# CMS32L032 register map
Vendor: CMS; Series: CMS32L032; File version: 1.2
CPU: CM0+ r0p1, little endian, no MPU, no FPU, VTOR, 2 interrupt priority bits
Registers are 8-bit, read-write, reset 0x0 unless marked. A register's access mark holds for its fields unless they carry their own. Offsets are from the block's base; [hi:lo] are bit positions; {n}, {i} and the like mark numbered series; 'fields as' and 'values as' point back to an identical list.

## SCI0 — Serial Communication Interface 0 with UART, SPI and simplified I2C supported
Base 0x40041100
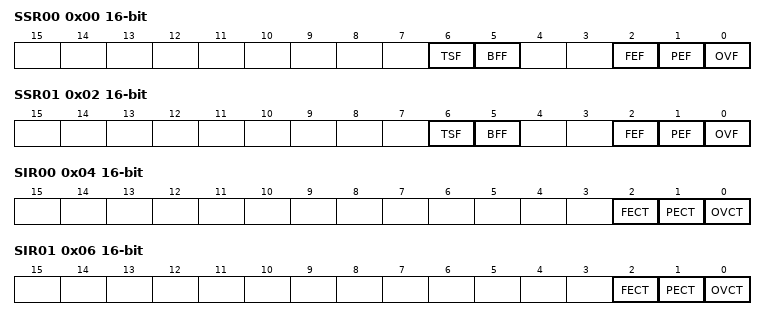
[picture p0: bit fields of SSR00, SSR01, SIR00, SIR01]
0x00 SSR00 16-bit ro — Serial status register mn
  [6] TSF — Communication status indication flag of channel n
  [5] BFF — Buffer register status indication flag of channel n
  [2] FEF — Framing error detection flag of channel n
  [1] PEF — Parity error detection flag of channel n
  [0] OVF — Overrun error detection flag of channel n
0x02 SSR01 16-bit ro — Serial status register mn
  fields as SSR00
0x04 SIR00 16-bit — Serial flag clear trigger register mn
  [2] FECT — Clear trigger of framing error flag of channel n
  [1] PECT — Clear trigger of parity error flag of channel n
  [0] OVCT — Clear trigger of overrun error flag of channel n
0x06 SIR01 16-bit — Serial flag clear trigger register mn
  fields as SIR00
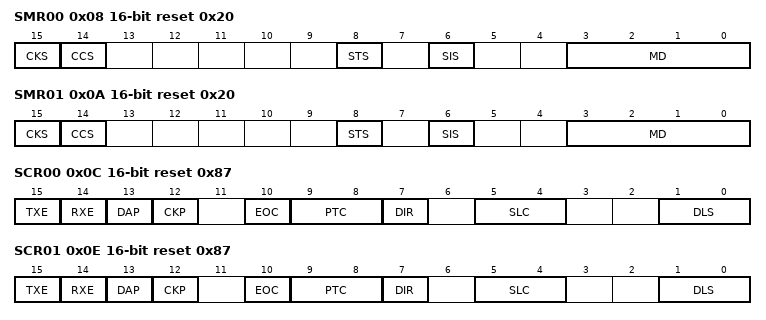
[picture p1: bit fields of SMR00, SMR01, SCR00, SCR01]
0x08 SMR00 16-bit reset 0x20 (reset mask 0xC147) — Serial mode register mn
  [15] CKS — Selection of operation clock (fMCK) of channel n
  [14] CCS — Selection of transfer clock (fTCLK) of channel n
  [8] STS — Selection of start trigger source
  [6] SIS — Controls inversion of level of receive data of channel n in UART mode
  [3:0] MD — Setting of operation mode of channel n
0x0A SMR01 16-bit reset 0x20 (reset mask 0xC147) — Serial mode register mn
  fields as SMR00
0x0C SCR00 16-bit reset 0x87 — Serial communication operation setting register mn
  [15] TXE — Transmission enable
  [14] RXE — Reception enable
  [13] DAP — Selection of data phase in SPI mode
  [12] CKP — Selection of clock phase in SPI mode
  [10] EOC — Mask control of error interrupt signal (INTSREx (x = 0 to 2))
  [9:8] PTC — Setting of parity bit in UART mode
  [7] DIR — Selection of data transfer sequence in SPI and UART modes
  [5:4] SLC — Setting of stop bit in UART mode
  [1:0] DLS — Setting of data length in SPI and UART modes
0x0E SCR01 16-bit reset 0x87 — Serial communication operation setting register mn
  fields as SCR00
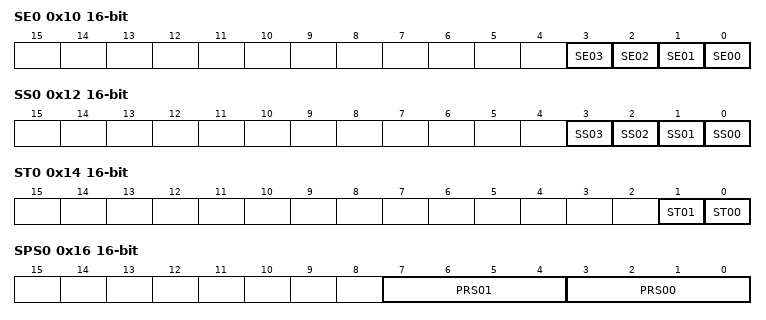
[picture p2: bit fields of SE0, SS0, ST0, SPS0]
0x10 SE0 16-bit ro — Serial channel enable status register m
  [n] SE{n:02} (n=0..3) — Indication of operation enable/stop status of channel {n}
0x12 SS0 16-bit — Serial channel start register 0
  [n] SS{n:02} (n=0..3) — Operation start trigger of channel {n}
0x14 ST0 16-bit — Serial channel stop register 0
  [1] ST01 — Operation stop trigger of channel 1
  [0] ST00 — Operation stop trigger of channel 0
0x16 SPS0 16-bit — Serial clock select register 0
  [7:4] PRS01 — Prescaler 1
  [3:0] PRS00 — Prescaler 0
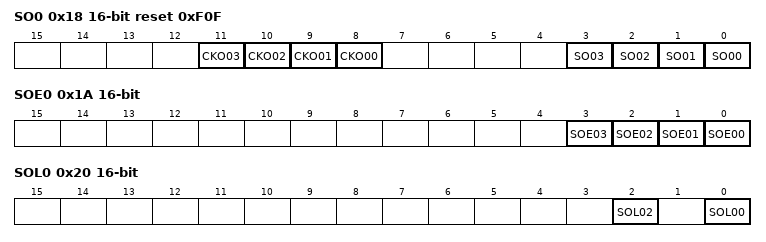
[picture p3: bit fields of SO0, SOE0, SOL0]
0x18 SO0 16-bit reset 0xF0F — Serial output register 0
  [n+8] CKO{n:02} (n=0..3) — Serial clock output of channel {n}
  [n] SO{n:02} (n=0..3) — Serial data output of channel {n}
0x1A SOE0 16-bit — Serial output enable register 0
  [n] SOE{n:02} (n=0..3) — Serial output enable of channel {n}
0x20 SOL0 16-bit — Serial output level register 0
  [2] SOL02 — Selects inversion of the level of the transmit data of channel n in UART mode
  [0] SOL00 — Selects inversion of the level of the transmit data of channel n in UART mode
0x22 SSE0 16-bit — Chip select register 0
  [0] SSE00 — Selects chip input
{0x40+2i} SDR0{i} (i=0..1) 16-bit — Serial data register 0{i}
0x40 SIO00 (alternate view of SDR00) — SPI data register
0x40 TXD0 (alternate view of SDR00) — UART transmit data register
0x42 SIO01 (alternate view of SDR01) — SPI data register
0x42 RXD0 (alternate view of SDR01) — UART receive data register

## SCI1 — Serial Communication Interface 1 with UART, SPI and simplified I2C supported
Base 0x40041500
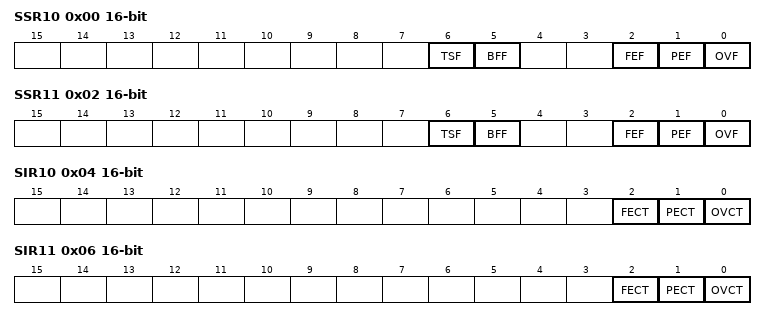
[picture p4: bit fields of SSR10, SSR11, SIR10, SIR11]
0x00 SSR10 16-bit ro — Serial status register mn
  [6] TSF — Communication status indication flag of channel n
  [5] BFF — Buffer register status indication flag of channel n
  [2] FEF — Framing error detection flag of channel n
  [1] PEF — Parity error detection flag of channel n
  [0] OVF — Overrun error detection flag of channel n
0x02 SSR11 16-bit ro — Serial status register mn
  fields as SSR10
0x04 SIR10 16-bit — Serial flag clear trigger register mn
  [2] FECT — Clear trigger of framing error flag of channel n
  [1] PECT — Clear trigger of parity error flag of channel n
  [0] OVCT — Clear trigger of overrun error flag of channel n
0x06 SIR11 16-bit — Serial flag clear trigger register mn
  fields as SIR10
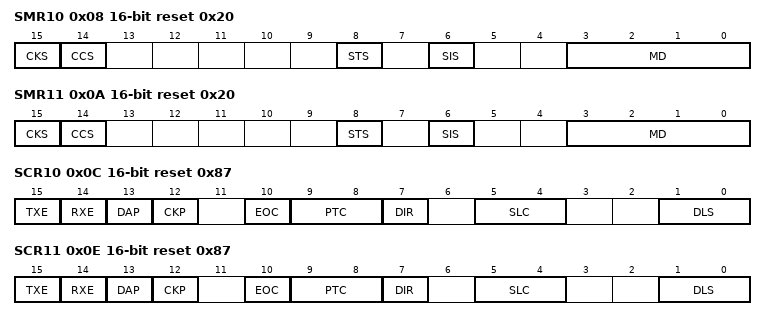
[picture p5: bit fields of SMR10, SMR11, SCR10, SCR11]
0x08 SMR10 16-bit reset 0x20 (reset mask 0xC147) — Serial mode register mn
  [15] CKS — Selection of operation clock (fMCK) of channel n
  [14] CCS — Selection of transfer clock (fTCLK) of channel n
  [8] STS — Selection of start trigger source
  [6] SIS — Controls inversion of level of receive data of channel n in UART mode
  [3:0] MD — Setting of operation mode of channel n
0x0A SMR11 16-bit reset 0x20 (reset mask 0xC147) — Serial mode register mn
  fields as SMR10
0x0C SCR10 16-bit reset 0x87 — Serial communication operation setting register mn
  [15] TXE — Transmission enable
  [14] RXE — Reception enable
  [13] DAP — Selection of data phase in SPI mode
  [12] CKP — Selection of clock phase in SPI mode
  [10] EOC — Mask control of error interrupt signal (INTSREx (x = 0 to 2))
  [9:8] PTC — Setting of parity bit in UART mode
  [7] DIR — Selection of data transfer sequence in SPI and UART modes
  [5:4] SLC — Setting of stop bit in UART mode
  [1:0] DLS — Setting of data length in SPI and UART modes
0x0E SCR11 16-bit reset 0x87 — Serial communication operation setting register mn
  fields as SCR10
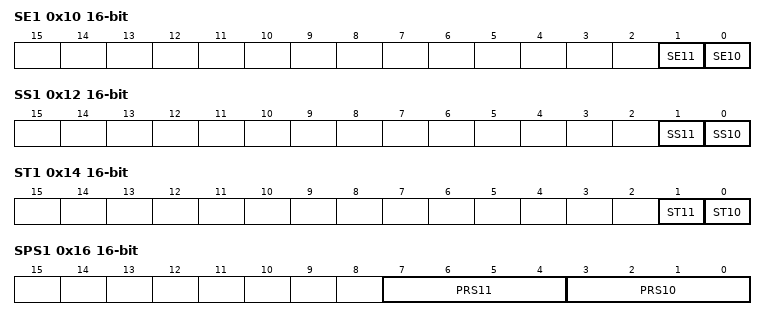
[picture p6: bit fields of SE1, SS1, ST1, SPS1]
0x10 SE1 16-bit ro — Serial channel enable status register 1
  [1] SE11 — Indication of operation enable/stop status of channel 1
  [0] SE10 — Indication of operation enable/stop status of channel 0
0x12 SS1 16-bit — Serial channel start register 1
  [1] SS11 — Operation start trigger of channel 1
  [0] SS10 — Operation start trigger of channel 0
0x14 ST1 16-bit — Serial channel stop register 1
  [1] ST11 — Operation stop trigger of channel 1
  [0] ST10 — Operation stop trigger of channel 0
0x16 SPS1 16-bit — Serial clock select register 1
  [7:4] PRS11 — Prescaler 1
  [3:0] PRS10 — Prescaler 0
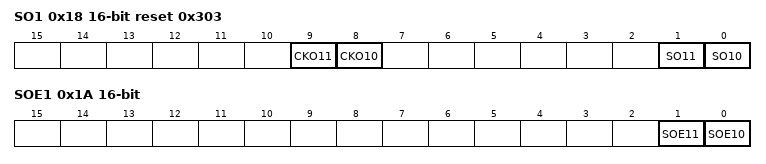
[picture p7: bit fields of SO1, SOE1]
0x18 SO1 16-bit reset 0x303 — Serial output register 1
  [9] CKO11 — Serial clock output of channel 1
  [8] CKO10 — Serial clock output of channel 0
  [1] SO11 — Serial data output of channel 1
  [0] SO10 — Serial data output of channel 0
0x1A SOE1 16-bit — Serial output enable register 1
  [1] SOE11 — Serial output enable of channel 1
  [0] SOE10 — Serial output enable of channel 0
0x20 SOL1 16-bit — Serial output level register 1
  [0] SOL10 — Selects inversion of the level of the transmit data of channel n in UART mode
0x22 SSE1 16-bit — Chip select register 1
  [0] SSE10 — Selects chip input
{0x40+2i} SDR1{i} (i=0..1) 16-bit — Serial data register 1{i}
0x40 SIO10 (alternate view of SDR10) — SPI data register
0x40 TXD1 (alternate view of SDR10) — UART transmit data register
0x42 SIO11 (alternate view of SDR11) — SPI data register
0x42 RXD1 (alternate view of SDR11) — UART receive data register
